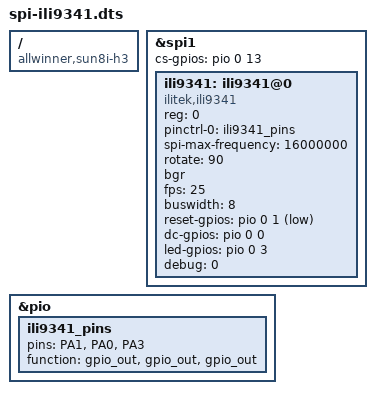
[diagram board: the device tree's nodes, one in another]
/dts-v1/;
/plugin/;

/ {
compatible = "allwinner,sun8i-h3";

  fragment@0 {
    target = <&spi1>;
    __overlay__ {

      status = "okay";
      #address-cells = <1>;
      #size-cells = <0>;
      cs-gpios = <&pio 0 13 0>; /* SPI1CS0 */
      ili9341: ili9341@0 {
        compatible = "ilitek,ili9341";
        reg = <0>;
        pinctrl-names = "default";
        pinctrl-0 = <&ili9341_pins>;

        spi-max-frequency = <16000000>;
        rotate = <90>;
        bgr;
        fps = <25>;
        buswidth = <8>;
        reset-gpios = <&pio 0 1 1>; /* GPIO 1, pin 11 */
        dc-gpios = <&pio 0 0 0>; /* GPIO 0, pin 13 */
        led-gpios = <&pio 0 3 0>; /* GPIO 3, pin 15 */
        debug = <0>;
      };
    };
  };

  fragment@1 {
    target = <&pio>;
    __overlay__ {
      ili9341_pins: ili9341_pins {
        pins = "PA1", "PA0", "PA3";
        function = "gpio_out", "gpio_out","gpio_out" ;
      };
    };
  };

};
